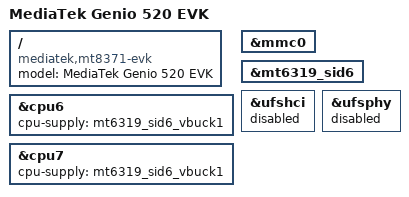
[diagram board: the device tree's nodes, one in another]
// SPDX-License-Identifier: (GPL-2.0 OR MIT)
/*
 * Copyright (c) 2025 Collabora Ltd.
 * Author: Louis-Alexis Eyraud <louisalexis.eyraud@collabora.com>
 */
/dts-v1/;

#include "mt8189.dtsi"
#include "mt8391-genio-common.dtsi"

/*
 * MT8371 SoC is a variant of the MT8189 with only one ISP engine
 * and lower maximum frequency on the big cores and on the Mali GPU.
 */

/ {
	model = "MediaTek Genio 520 EVK";
	compatible = "mediatek,mt8371-evk", "mediatek,mt8371",
		     "mediatek,mt8189";
};

&cpu6 {
	cpu-supply = <&mt6319_sid6_vbuck1>;
};

&cpu7 {
	cpu-supply = <&mt6319_sid6_vbuck1>;
};

&mmc0 {
	status = "okay";
};

&mt6319_sid6 {
	status = "okay";
};

&ufshci {
	status = "disabled";
};

&ufsphy {
	status = "disabled";
};
